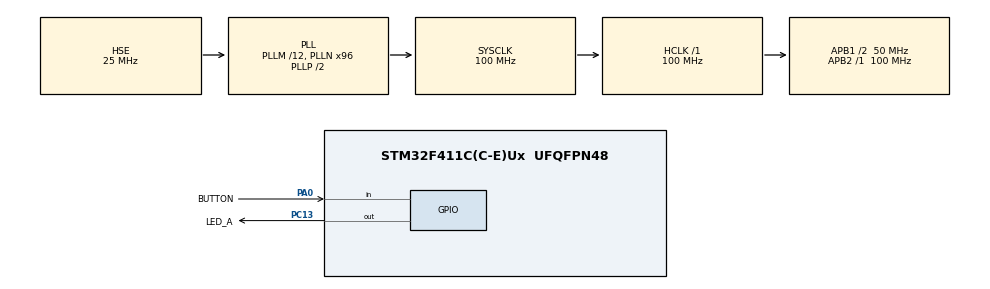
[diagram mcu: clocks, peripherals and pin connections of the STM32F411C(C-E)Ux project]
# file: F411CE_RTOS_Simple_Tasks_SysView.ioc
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Mcu.Family=STM32F4
RCC.PLLSourceVirtual=RCC_PLLSOURCE_HSE
PC15-OSC32_OUT.Mode=LSE-External-Oscillator
RCC.CortexFreq_Value=100000000
FREERTOS.Tasks01=Task_A,24,128,Task_A_Main,Default,NULL,Dynamic,NULL,NULL;Task_B,24,128,Task_B_Main,Default,NULL,Dynamic,NULL,NULL;Task_C,24,128,Task_C_Main,Default,NULL,Dynamic,NULL,NULL
PC13-ANTI_TAMP.GPIO_Label=LED_A
PH1\ -\ OSC_OUT.Mode=HSE-External-Oscillator
RCC.APB1CLKDivider=RCC_HCLK_DIV2
PC14-OSC32_IN.Signal=RCC_OSC32_IN
RCC.SYSCLKSource=RCC_SYSCLKSOURCE_PLLCLK
ProjectManager.StackSize=0x400
PA0-WKUP.GPIO_Label=BUTTON
PA0-WKUP.Signal=GPIO_Input
VP_FREERTOS_VS_CMSIS_V2.Mode=CMSIS_V2
PA13.Signal=SYS_JTMS-SWDIO
PH0\ -\ OSC_IN.Mode=HSE-External-Oscillator
PH0\ -\ OSC_IN.Signal=RCC_OSC_IN
ProjectManager.TargetToolchain=STM32CubeIDE
RCC.HCLKFreq_Value=100000000
RCC.APB2TimFreq_Value=100000000
PC15-OSC32_OUT.Signal=RCC_OSC32_OUT
RCC.AHBFreq_Value=100000000
NVIC.TIM1_TRG_COM_TIM11_IRQn=true\:0\:0\:false\:false\:true\:false\:false\:true
RCC.HSE_VALUE=25000000
PH1\ -\ OSC_OUT.Signal=RCC_OSC_OUT
PB3.Mode=Trace_Asynchronous_SW
board=custom
PC13-ANTI_TAMP.Signal=GPIO_Output
RCC.VCOOutputFreq_Value=200000000
RCC.APB2Freq_Value=100000000
PC14-OSC32_IN.Mode=LSE-External-Oscillator
PA14.Mode=Trace_Asynchronous_SW
PA13.Mode=Trace_Asynchronous_SW
Mcu.Name=STM32F411C(C-E)Ux
VP_SYS_VS_tim11.Mode=TIM11
RCC.48MHZClocksFreq_Value=50000000
PB3.Signal=SYS_JTDO-SWO
RCC.SYSCLKFreq_VALUE=100000000
Mcu.Package=UFQFPN48
NVIC.TimeBase=TIM1_TRG_COM_TIM11_IRQn
NVIC.TimeBaseIP=TIM11
PA14.Signal=SYS_JTCK-SWCLK
ProjectManager.HeapSize=0x200
FREERTOS.Timers01=Timer5s,Timer5sCallback,osTimerPeriodic,Default,NULL,Dynamic,NULL
RCC.HSI_VALUE=16000000
NVIC.PriorityGroup=NVIC_PRIORITYGROUP_4
RCC.PLLM=12
RCC.PLLN=96
RCC.APB1TimFreq_Value=100000000
PA0-WKUP.GPIO_PuPd=GPIO_PULLUP
RCC.APB1Freq_Value=50000000

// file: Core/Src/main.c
/* USER CODE BEGIN Header */
/**
  ******************************************************************************
  * @file           : main.c
  * @brief          : Main program body
  ******************************************************************************
  * @attention
  *
  * <h2><center>&copy; Copyright (c) 2021 STMicroelectronics.
  * All rights reserved.</center></h2>
  *
  * This software component is licensed by ST under BSD 3-Clause license,
  * the "License"; You may not use this file except in compliance with the
  * License. You may obtain a copy of the License at:
  *                        opensource.org/licenses/BSD-3-Clause
  *
  ******************************************************************************
  */
/* USER CODE END Header */
#include "main.h"
#include "cmsis_os.h"

/* USER CODE BEGIN Includes */
#include "SEGGER_SYSVIEW.h"
/* USER CODE END Includes */

/* Definitions for Task_A */
osThreadId_t Task_AHandle;
const osThreadAttr_t Task_A_attributes = {
  .name = "Task_A",
  .stack_size = 128 * 4,
  .priority = (osPriority_t) osPriorityNormal,
};
/* Definitions for Task_B */
osThreadId_t Task_BHandle;
const osThreadAttr_t Task_B_attributes = {
  .name = "Task_B",
  .stack_size = 128 * 4,
  .priority = (osPriority_t) osPriorityNormal,
};
/* Definitions for Task_C */
osThreadId_t Task_CHandle;
const osThreadAttr_t Task_C_attributes = {
  .name = "Task_C",
  .stack_size = 128 * 4,
  .priority = (osPriority_t) osPriorityNormal,
};
/* Definitions for Timer5s */
osTimerId_t Timer5sHandle;
const osTimerAttr_t Timer5s_attributes = {
  .name = "Timer5s"
};
/* USER CODE BEGIN PV */
char isButtonPressed = 0;
/* USER CODE END PV */

void SystemClock_Config(void);
static void MX_GPIO_Init(void);
void Task_A_Main(void *argument);
void Task_B_Main(void *argument);
void Task_C_Main(void *argument);
void Timer5sCallback(void *argument);

int main(void)
{

  /* MCU Configuration--------------------------------------------------------*/

  /* Reset of all peripherals, Initializes the Flash interface and the Systick. */
  HAL_Init();

  /* Configure the system clock */
  SystemClock_Config();

  /* Initialize all configured peripherals */
  MX_GPIO_Init();
  /* USER CODE BEGIN 2 */
  SEGGER_SYSVIEW_Conf();
  /* USER CODE END 2 */

  /* Init scheduler */
  osKernelInitialize();

  /* Create the timer(s) */
  /* creation of Timer5s */
  Timer5sHandle = osTimerNew(Timer5sCallback, osTimerPeriodic, NULL, &Timer5s_attributes);

  /* Create the thread(s) */
  /* creation of Task_A */
  Task_AHandle = osThreadNew(Task_A_Main, NULL, &Task_A_attributes);

  /* creation of Task_B */
  Task_BHandle = osThreadNew(Task_B_Main, NULL, &Task_B_attributes);

  /* creation of Task_C */
  Task_CHandle = osThreadNew(Task_C_Main, NULL, &Task_C_attributes);

  /* Start scheduler */
  osKernelStart();

  /* We should never get here as control is now taken by the scheduler */
  /* Infinite loop */
  while (1)
  {

  }
}

void SystemClock_Config(void)
{
  RCC_OscInitTypeDef RCC_OscInitStruct = {0};
  RCC_ClkInitTypeDef RCC_ClkInitStruct = {0};

  /** Configure the main internal regulator output voltage
  */
  __HAL_RCC_PWR_CLK_ENABLE();
  __HAL_PWR_VOLTAGESCALING_CONFIG(PWR_REGULATOR_VOLTAGE_SCALE1);
  /** Initializes the RCC Oscillators according to the specified parameters
  * in the RCC_OscInitTypeDef structure.
  */
  RCC_OscInitStruct.OscillatorType = RCC_OSCILLATORTYPE_HSE;
  RCC_OscInitStruct.HSEState = RCC_HSE_ON;
  RCC_OscInitStruct.PLL.PLLState = RCC_PLL_ON;
  RCC_OscInitStruct.PLL.PLLSource = RCC_PLLSOURCE_HSE;
  RCC_OscInitStruct.PLL.PLLM = 12;
  RCC_OscInitStruct.PLL.PLLN = 96;
  RCC_OscInitStruct.PLL.PLLP = RCC_PLLP_DIV2;
  RCC_OscInitStruct.PLL.PLLQ = 4;
  if (HAL_RCC_OscConfig(&RCC_OscInitStruct) != HAL_OK)
  {
    Error_Handler();
  }
  /** Initializes the CPU, AHB and APB buses clocks
  */
  RCC_ClkInitStruct.ClockType = RCC_CLOCKTYPE_HCLK|RCC_CLOCKTYPE_SYSCLK
                              |RCC_CLOCKTYPE_PCLK1|RCC_CLOCKTYPE_PCLK2;
  RCC_ClkInitStruct.SYSCLKSource = RCC_SYSCLKSOURCE_PLLCLK;
  RCC_ClkInitStruct.AHBCLKDivider = RCC_SYSCLK_DIV1;
  RCC_ClkInitStruct.APB1CLKDivider = RCC_HCLK_DIV2;
  RCC_ClkInitStruct.APB2CLKDivider = RCC_HCLK_DIV1;

  if (HAL_RCC_ClockConfig(&RCC_ClkInitStruct, FLASH_LATENCY_3) != HAL_OK)
  {
    Error_Handler();
  }
}

static void MX_GPIO_Init(void)
{
  GPIO_InitTypeDef GPIO_InitStruct = {0};

  /* GPIO Ports Clock Enable */
  __HAL_RCC_GPIOC_CLK_ENABLE();
  __HAL_RCC_GPIOH_CLK_ENABLE();
  __HAL_RCC_GPIOA_CLK_ENABLE();
  __HAL_RCC_GPIOB_CLK_ENABLE();

  /*Configure GPIO pin Output Level */
  HAL_GPIO_WritePin(LED_A_GPIO_Port, LED_A_Pin, GPIO_PIN_RESET);

  /*Configure GPIO pin : LED_A_Pin */
  GPIO_InitStruct.Pin = LED_A_Pin;
  GPIO_InitStruct.Mode = GPIO_MODE_OUTPUT_PP;
  GPIO_InitStruct.Pull = GPIO_NOPULL;
  GPIO_InitStruct.Speed = GPIO_SPEED_FREQ_LOW;
  HAL_GPIO_Init(LED_A_GPIO_Port, &GPIO_InitStruct);

  /*Configure GPIO pin : BUTTON_Pin */
  GPIO_InitStruct.Pin = BUTTON_Pin;
  GPIO_InitStruct.Mode = GPIO_MODE_INPUT;
  GPIO_InitStruct.Pull = GPIO_PULLUP;
  HAL_GPIO_Init(BUTTON_GPIO_Port, &GPIO_InitStruct);

}

void Task_A_Main(void *argument)
{
  /* USER CODE BEGIN 5 */
  /* Infinite loop */
  for(;;)
  {
    if(!isButtonPressed) HAL_GPIO_TogglePin(LED_A_GPIO_Port, LED_A_Pin);
    osDelay(100);
  }
  /* USER CODE END 5 */
}

void Task_B_Main(void *argument)
{
  /* USER CODE BEGIN Task_B_Main */
  /* Infinite loop */
  for(;;)
  {
    osDelay(10);
  }
  /* USER CODE END Task_B_Main */
}

void Task_C_Main(void *argument)
{
  /* USER CODE BEGIN Task_C_Main */
  /* Infinite loop */
  for(;;)
  {
    if (HAL_GPIO_ReadPin(BUTTON_GPIO_Port, BUTTON_Pin) == GPIO_PIN_RESET) {
      isButtonPressed = 1;
      osTimerStart(Timer5sHandle, 5000);
    }
    osDelay(100);
  }
  /* USER CODE END Task_C_Main */
}

/* Timer5sCallback function */
void Timer5sCallback(void *argument)
{
  /* USER CODE BEGIN Timer5sCallback */
  isButtonPressed = 0;
  /* USER CODE END Timer5sCallback */
}

 /**
  * @brief  Period elapsed callback in non blocking mode
  * @note   This function is called  when TIM11 interrupt took place, inside
  * HAL_TIM_IRQHandler(). It makes a direct call to HAL_IncTick() to increment
  * a global variable "uwTick" used as application time base.
  * @param  htim : TIM handle
  * @retval None
  */
void HAL_TIM_PeriodElapsedCallback(TIM_HandleTypeDef *htim)
{
  if (htim->Instance == TIM11) {
    HAL_IncTick();
  }
}

void Error_Handler(void)
{
  __disable_irq();
  while (1)
  {
  }
}

/************************ (C) COPYRIGHT STMicroelectronics *****END OF FILE****/
